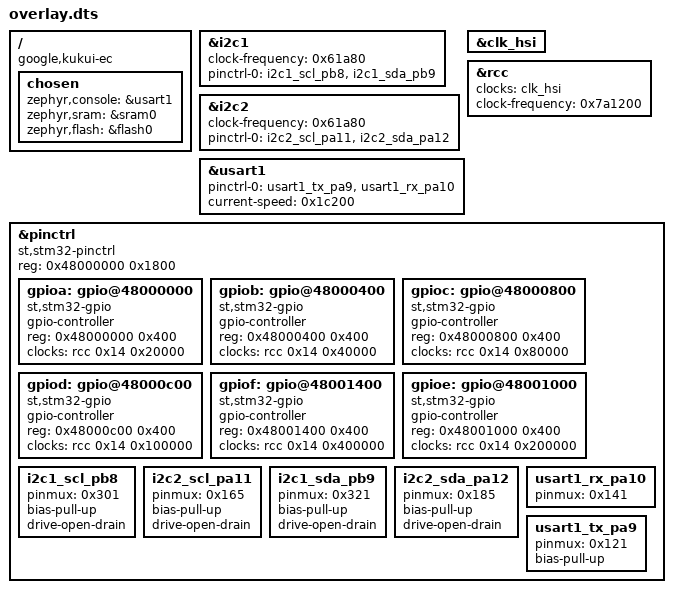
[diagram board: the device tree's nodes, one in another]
/ {
	compatible = "google,kukui-ec", "st,stm32f098";
	chosen {
		zephyr,console = &usart1;
		zephyr,sram = &sram0;
		zephyr,flash = &flash0;
	};
};
&i2c1{
	clock-frequency = < 0x61a80 >;
	status = "okay";
	pinctrl-0 = < &i2c1_scl_pb8 &i2c1_sda_pb9 >;
	pinctrl-names = "default";
};
&i2c2{
	clock-frequency = < 0x61a80 >;
	status = "okay";
	pinctrl-0 = < &i2c2_scl_pa11 &i2c2_sda_pa12 >;
	pinctrl-names = "default";
};
&clk_hsi{
	status = "okay";
};
&rcc{
	clocks = < &clk_hsi >;
	clock-frequency = < 0x7a1200 >;
};
&usart1{
	status = "okay";
	pinctrl-0 = < &usart1_tx_pa9 &usart1_rx_pa10 >;
	pinctrl-names = "default";
	current-speed = < 0x1c200 >;
};
&pinctrl{
	compatible = "st,stm32-pinctrl";
	#address-cells = < 0x1 >;
	#size-cells = < 0x1 >;
	reg = < 0x48000000 0x1800 >;
	gpioa: gpio@48000000 {
		compatible = "st,stm32-gpio";
		gpio-controller;
		#gpio-cells = < 0x2 >;
		reg = < 0x48000000 0x400 >;
		clocks = < &rcc 0x14 0x20000 >;
	};
	gpiob: gpio@48000400 {
		compatible = "st,stm32-gpio";
		gpio-controller;
		#gpio-cells = < 0x2 >;
		reg = < 0x48000400 0x400 >;
		clocks = < &rcc 0x14 0x40000 >;
	};
	gpioc: gpio@48000800 {
		compatible = "st,stm32-gpio";
		gpio-controller;
		#gpio-cells = < 0x2 >;
		reg = < 0x48000800 0x400 >;
		clocks = < &rcc 0x14 0x80000 >;
	};
	gpiod: gpio@48000c00 {
		compatible = "st,stm32-gpio";
		gpio-controller;
		#gpio-cells = < 0x2 >;
		reg = < 0x48000c00 0x400 >;
		clocks = < &rcc 0x14 0x100000 >;
	};
	gpiof: gpio@48001400 {
		compatible = "st,stm32-gpio";
		gpio-controller;
		#gpio-cells = < 0x2 >;
		reg = < 0x48001400 0x400 >;
		clocks = < &rcc 0x14 0x400000 >;
	};
	gpioe: gpio@48001000 {
		compatible = "st,stm32-gpio";
		gpio-controller;
		#gpio-cells = < 0x2 >;
		reg = < 0x48001000 0x400 >;
		clocks = < &rcc 0x14 0x200000 >;
	};
	i2c1_scl_pb8: i2c1_scl_pb8 {
		pinmux = < 0x301 >;
		bias-pull-up;
		drive-open-drain;
	};
	i2c2_scl_pa11: i2c2_scl_pa11 {
		pinmux = < 0x165 >;
		bias-pull-up;
		drive-open-drain;
	};
	i2c1_sda_pb9: i2c1_sda_pb9 {
		pinmux = < 0x321 >;
		bias-pull-up;
		drive-open-drain;
	};
	i2c2_sda_pa12: i2c2_sda_pa12 {
		pinmux = < 0x185 >;
		bias-pull-up;
		drive-open-drain;
	};
	usart1_rx_pa10: usart1_rx_pa10 {
		pinmux = < 0x141 >;
	};
	usart1_tx_pa9: usart1_tx_pa9 {
		pinmux = < 0x121 >;
		bias-pull-up;
	};
};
